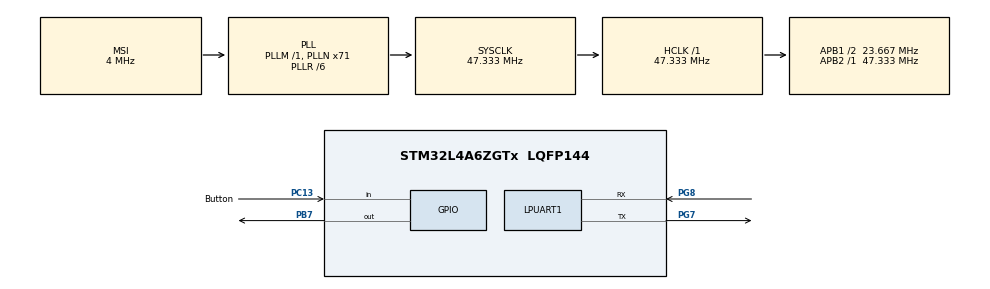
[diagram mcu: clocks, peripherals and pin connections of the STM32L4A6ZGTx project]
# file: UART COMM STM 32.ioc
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LPUART1.WordLength=UART_WORDLENGTH_8B
Mcu.Family=STM32L4
Mcu.Name=STM32L4A6ZGTx
Mcu.Package=LQFP144
NVIC.PriorityGroup=NVIC_PRIORITYGROUP_4
PB7.GPIO_Speed=GPIO_SPEED_FREQ_HIGH
PB7.PinState=GPIO_PIN_RESET
PB7.Signal=GPIO_Output
PC13.GPIO_Label=Button
PC13.GPIO_Mode=GPIO_MODE_INPUT
PC13.Signal=GPIO_Input
PG7.Mode=Asynchronous
PG7.Signal=LPUART1_TX
PG8.Mode=Asynchronous
PG8.Signal=LPUART1_RX
PH0-OSC_IN\ (PH0).Mode=HSE-External-Oscillator
PH0-OSC_IN\ (PH0).Signal=RCC_OSC_IN
PH1-OSC_OUT\ (PH1).Mode=HSE-External-Oscillator
PH1-OSC_OUT\ (PH1).Signal=RCC_OSC_OUT
ProjectManager.HeapSize=0x200
ProjectManager.StackSize=0x400
ProjectManager.TargetToolchain=STM32CubeIDE
RCC.ADCFreq_Value=48000000
RCC.AHBFreq_Value=47333333.333333336
RCC.APB1CLKDivider=RCC_HCLK_DIV2
RCC.APB1Freq_Value=23666666.666666668
RCC.APB1TimFreq_Value=47333333.333333336
RCC.APB2Freq_Value=47333333.333333336
RCC.APB2TimFreq_Value=47333333.333333336
RCC.CortexFreq_Value=47333333.333333336
RCC.FLatency=FLASH_LATENCY_2
RCC.HCLKFreq_Value=47333333.333333336
RCC.HSE_VALUE=8000000
RCC.HSI48_VALUE=48000000
RCC.HSI_VALUE=16000000
RCC.MSI_VALUE=4000000
RCC.PLLN=71
RCC.PLLR=RCC_PLLR_DIV6
RCC.PLLSAI1N=24
RCC.SYSCLKFreq_VALUE=47333333.333333336
RCC.SYSCLKSource=RCC_SYSCLKSOURCE_PLLCLK
RCC.USBFreq_Value=48000000
RCC.VCOOutputFreq_Value=284000000
board=NUCLEO-L4A6ZG

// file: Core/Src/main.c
/* USER CODE BEGIN Header */
/**
  ******************************************************************************
  * @file           : main.c
  * @brief          : Main program body
  ******************************************************************************
  * @attention
  *
  * Copyright (c) 2024 STMicroelectronics.
  * All rights reserved.
  *
  * This software is licensed under terms that can be found in the LICENSE file
  * in the root directory of this software component.
  * If no LICENSE file comes with this software, it is provided AS-IS.
  *
  ******************************************************************************
  */
/* USER CODE END Header */
#include "main.h"

/* USER CODE BEGIN Includes */
#define BUTTON_PIN GPIO_PIN_13
#define BUTTON_GPIO_PORT GPIOC
#define LED_PIN GPIO_PIN_7
#define LED_GPIO_PORT GPIOB
/* USER CODE END Includes */

UART_HandleTypeDef hlpuart1;

/* USER CODE BEGIN PV */
uint8_t tx_buffer[100]="Hello This Communication is being done through UART!\n\r";
uint8_t rx_data[2];
uint8_t rx_indx;
uint8_t rx_buffer[100];
uint8_t transfer_cplt;
/* USER CODE END PV */

void SystemClock_Config(void);
static void MX_GPIO_Init(void);
static void MX_LPUART1_UART_Init(void);

int main(void)
{

  /* MCU Configuration--------------------------------------------------------*/

  /* Reset of all peripherals, Initializes the Flash interface and the Systick. */
  HAL_Init();

  /* Configure the system clock */
  SystemClock_Config();

  /* Initialize all configured peripherals */
  MX_GPIO_Init();
  MX_LPUART1_UART_Init();
  /* USER CODE BEGIN 2 */
HAL_UART_Receive_IT(&hlpuart1, rx_data, 1);
  /* USER CODE END 2 */

  /* Infinite loop */
  /* USER CODE BEGIN WHILE */
  while (1)
  {
//    /* USER CODE END WHILE */
//      if (HAL_GPIO_ReadPin(BUTTON_GPIO_PORT, BUTTON_PIN) == GPIO_PIN_SET) {
//
//          HAL_GPIO_WritePin(LED_GPIO_PORT, LED_PIN, GPIO_PIN_SET);
//
//          HAL_UART_Transmit(&hlpuart1, tx_buffer, 100, 10);
//
//
//          HAL_Delay(300);
//
//
//          while (HAL_GPIO_ReadPin(BUTTON_GPIO_PORT, BUTTON_PIN) == GPIO_PIN_SET) {
//
//          }
//
//
//          HAL_GPIO_WritePin(LED_GPIO_PORT, LED_PIN, GPIO_PIN_RESET);
//      }
//    /* USER CODE BEGIN 3 */
  }
  /* USER CODE END 3 */
}

void SystemClock_Config(void)
{
  RCC_OscInitTypeDef RCC_OscInitStruct = {0};
  RCC_ClkInitTypeDef RCC_ClkInitStruct = {0};

  /** Configure the main internal regulator output voltage
  */
  if (HAL_PWREx_ControlVoltageScaling(PWR_REGULATOR_VOLTAGE_SCALE1) != HAL_OK)
  {
    Error_Handler();
  }

  /** Initializes the RCC Oscillators according to the specified parameters
  * in the RCC_OscInitTypeDef structure.
  */
  RCC_OscInitStruct.OscillatorType = RCC_OSCILLATORTYPE_MSI;
  RCC_OscInitStruct.MSIState = RCC_MSI_ON;
  RCC_OscInitStruct.MSICalibrationValue = 0;
  RCC_OscInitStruct.MSIClockRange = RCC_MSIRANGE_6;
  RCC_OscInitStruct.PLL.PLLState = RCC_PLL_ON;
  RCC_OscInitStruct.PLL.PLLSource = RCC_PLLSOURCE_MSI;
  RCC_OscInitStruct.PLL.PLLM = 1;
  RCC_OscInitStruct.PLL.PLLN = 71;
  RCC_OscInitStruct.PLL.PLLP = RCC_PLLP_DIV2;
  RCC_OscInitStruct.PLL.PLLQ = RCC_PLLQ_DIV2;
  RCC_OscInitStruct.PLL.PLLR = RCC_PLLR_DIV6;
  if (HAL_RCC_OscConfig(&RCC_OscInitStruct) != HAL_OK)
  {
    Error_Handler();
  }

  /** Initializes the CPU, AHB and APB buses clocks
  */
  RCC_ClkInitStruct.ClockType = RCC_CLOCKTYPE_HCLK|RCC_CLOCKTYPE_SYSCLK
                              |RCC_CLOCKTYPE_PCLK1|RCC_CLOCKTYPE_PCLK2;
  RCC_ClkInitStruct.SYSCLKSource = RCC_SYSCLKSOURCE_PLLCLK;
  RCC_ClkInitStruct.AHBCLKDivider = RCC_SYSCLK_DIV1;
  RCC_ClkInitStruct.APB1CLKDivider = RCC_HCLK_DIV2;
  RCC_ClkInitStruct.APB2CLKDivider = RCC_HCLK_DIV1;

  if (HAL_RCC_ClockConfig(&RCC_ClkInitStruct, FLASH_LATENCY_2) != HAL_OK)
  {
    Error_Handler();
  }
}

static void MX_LPUART1_UART_Init(void)
{

  hlpuart1.Instance = LPUART1;
  hlpuart1.Init.BaudRate = 209700;
  hlpuart1.Init.WordLength = UART_WORDLENGTH_8B;
  hlpuart1.Init.StopBits = UART_STOPBITS_1;
  hlpuart1.Init.Parity = UART_PARITY_NONE;
  hlpuart1.Init.Mode = UART_MODE_TX_RX;
  hlpuart1.Init.HwFlowCtl = UART_HWCONTROL_NONE;
  hlpuart1.Init.OneBitSampling = UART_ONE_BIT_SAMPLE_DISABLE;
  hlpuart1.AdvancedInit.AdvFeatureInit = UART_ADVFEATURE_NO_INIT;
  if (HAL_UART_Init(&hlpuart1) != HAL_OK)
  {
    Error_Handler();
  }

}

static void MX_GPIO_Init(void)
{
  GPIO_InitTypeDef GPIO_InitStruct = {0};

  /* GPIO Ports Clock Enable */
  __HAL_RCC_GPIOC_CLK_ENABLE();
  __HAL_RCC_GPIOH_CLK_ENABLE();
  __HAL_RCC_GPIOG_CLK_ENABLE();
  HAL_PWREx_EnableVddIO2();
  __HAL_RCC_GPIOB_CLK_ENABLE();

  /*Configure GPIO pin Output Level */
  HAL_GPIO_WritePin(GPIOB, GPIO_PIN_7, GPIO_PIN_RESET);

  /*Configure GPIO pin : Button_Pin */
  GPIO_InitStruct.Pin = Button_Pin;
  GPIO_InitStruct.Mode = GPIO_MODE_INPUT;
  GPIO_InitStruct.Pull = GPIO_NOPULL;
  HAL_GPIO_Init(Button_GPIO_Port, &GPIO_InitStruct);

  /*Configure GPIO pin : PB7 */
  GPIO_InitStruct.Pin = GPIO_PIN_7;
  GPIO_InitStruct.Mode = GPIO_MODE_OUTPUT_PP;
  GPIO_InitStruct.Pull = GPIO_NOPULL;
  GPIO_InitStruct.Speed = GPIO_SPEED_FREQ_HIGH;
  HAL_GPIO_Init(GPIOB, &GPIO_InitStruct);

}

/* USER CODE BEGIN 4 */
void HAL_UART_RxCpltCallback(UART_HandleTypeDef *huart)
{
  /* Prevent unused argument(s) compilation warning */
  UNUSED(huart);

  HAL_UART_Transmit(&hlpuart1, rx_data, 6,10);

  /* NOTE : This function should not be modified, when the callback is needed,
            the HAL_UART_RxCpltCallback can be implemented in the user file.*

}
/* USER CODE END 4 */

/**
  * @brief  This function is executed in case of error occurrence.
  * @retval None
  */}
void Error_Handler(void)
{
  __disable_irq();
  while (1)
  {
  }
  }
